# APM32F411 register map
Vendor: Geehy; File version: 2024.11.05
CPU: CM4 r1p0, little endian, 3 interrupt priority bits
Registers are 32-bit, read-write, reset 0x0 unless marked. A register's access mark holds for its fields unless they carry their own. Offsets are from the block's base; [hi:lo] are bit positions.

## I2C1 — Inter-integrated circuit
Base 0x40005400
Same registers: I2C2 0x40005800, I2C3 0x40005C00
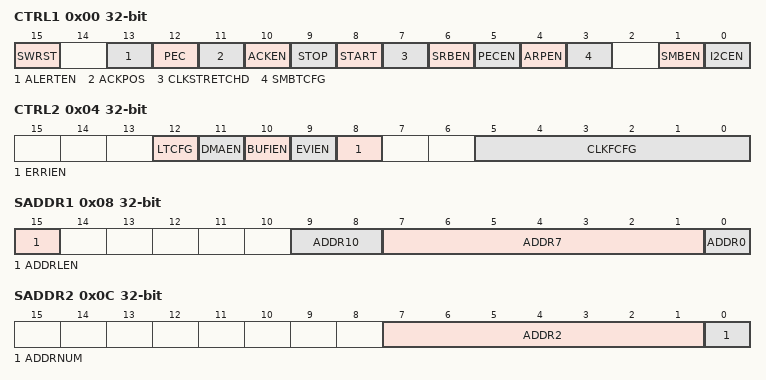
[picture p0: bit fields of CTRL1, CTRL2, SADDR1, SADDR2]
0x00 CTRL1 — Control register 1
  [15] SWRST — Software reset
  [13] ALERTEN — SMBus alert
  [12] PEC — Packet error checking
  [11] ACKPOS — Acknowledge/PEC Position (for data reception)
  [10] ACKEN — Acknowledge enable
  [9] STOP — Stop generation
  [8] START — Start generation
  [7] CLKSTRETCHD — Clock stretching disable (Slave mode)
  [6] SRBEN — General call enable
  [5] PECEN — PEC enable
  [4] ARPEN — ARP enable
  [3] SMBTCFG — SMBus type
  [1] SMBEN — SMBus mode
  [0] I2CEN — I2C enable
0x04 CTRL2 — Control register 2
  [12] LTCFG — DMA last transfer
  [11] DMAEN — DMA requests enable
  [10] BUFIEN — Buffer interrupt enable
  [9] EVIEN — Event interrupt enable
  [8] ERRIEN — Error interrupt enable
  [5:0] CLKFCFG — I2C clock frequency
0x08 SADDR1 — Own address register 1
  [15] ADDRLEN — Addressing mode (slave mode)
  [9:8] ADDR10 — Interface address
  [7:1] ADDR7 — Interface address
  [0] ADDR0 — Interface address
0x0C SADDR2 — Own address register 2
  [7:1] ADDR2 — Interface address
  [0] ADDRNUM — Slave Address Number Configure
0x10 DATA
  [7:0] DATA — 8-bit data register
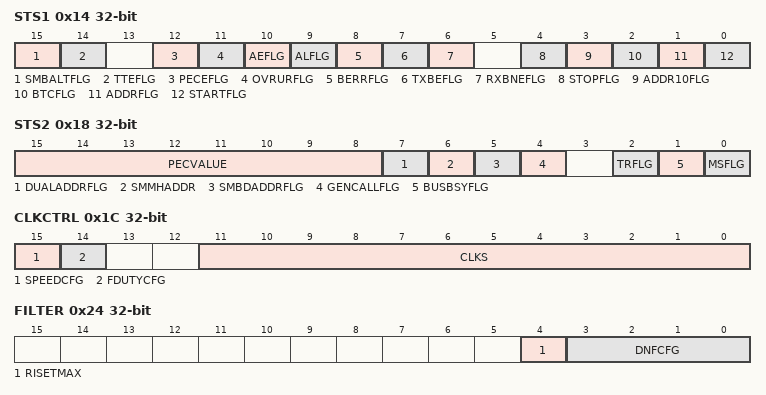
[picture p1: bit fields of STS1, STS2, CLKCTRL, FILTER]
0x14 STS1 access per field — Status register 1
  [15] SMBALTFLG rw — SMBus alert
  [14] TTEFLG rw — Timeout or Tlow error
  [12] PECEFLG rw — PEC Error in reception
  [11] OVRURFLG rw — Overrun/Underrun
  [10] AEFLG rw — Acknowledge failure
  [9] ALFLG rw — Arbitration lost (master mode)
  [8] BERRFLG rw — Bus error
  [7] TXBEFLG ro — Data register empty (transmitters)
  [6] RXBNEFLG ro — Data register not empty (receivers)
  [4] STOPFLG ro — Stop detection (slave mode)
  [3] ADDR10FLG ro — 10-bit header sent (Master mode)
  [2] BTCFLG ro — Byte transfer finished
  [1] ADDRFLG ro — Address sent (master mode)/matched (slavemode)
  [0] STARTFLG ro — Start bit (Master mode)
0x18 STS2 ro — Status register 2
  [15:8] PECVALUE — Save Packet Error Checking Value
  [7] DUALADDRFLG — Dual flag (Slave mode)
  [6] SMMHADDR — SMBus host header (Slave mode)
  [5] SMBDADDRFLG — SMBus device default address (Slave mode)
  [4] GENCALLFLG — General call address (Slave mode)
  [2] TRFLG — Transmitter/receiver
  [1] BUSBSYFLG — Bus busy
  [0] MSFLG — Master Slave Mode Flag
0x1C CLKCTRL — Clock control register
  [15] SPEEDCFG — Master Mode Speed Configure
  [14] FDUTYCFG — Fast mode duty cycle
  [11:0] CLKS — Clock control register in Fast/Standard mode(Master mode)
0x20 RISETMAX reset 0x2 — Maximum Rise Time register
  [5:0] RISETMAX — Maximum rise time in Fast/Standard mode (Master mode)
0x24 FILTER — Filter control register
  [4] RISETMAX — Analog Noise Filter Disable
  [3:0] DNFCFG — Digitial Noise Filter Filtering Capabitity Configure

## I2S2ext — Serial peripheral interface
Base 0x40003400
Same registers: SPI2 0x40003800, SPI3 0x40003C00, I2S3ext 0x40004000, SPI1 0x40013000, SPI4 0x40013400, SPI5 0x40015000
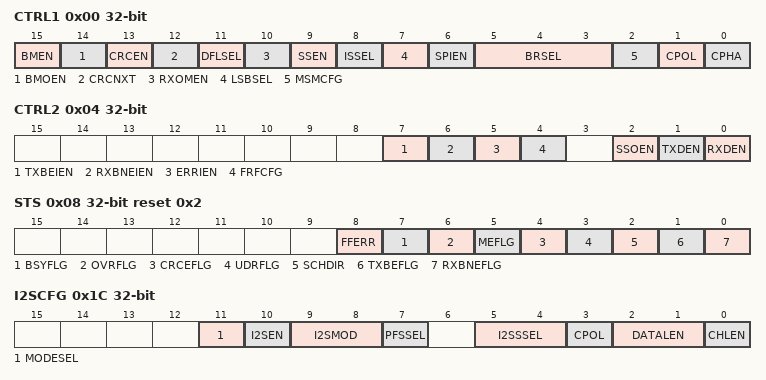
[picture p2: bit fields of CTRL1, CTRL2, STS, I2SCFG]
0x00 CTRL1 — control register 1
  [15] BMEN — Bidirectional data mode enable
  [14] BMOEN — Output enable in bidirectional mode
  [13] CRCEN — Hardware CRC calculation enable
  [12] CRCNXT — CRC transfer next
  [11] DFLSEL — Data frame format
  [10] RXOMEN — Receive only
  [9] SSEN — Software slave management
  [8] ISSEL — Internal slave select
  [7] LSBSEL — Frame format
  [6] SPIEN — SPI enable
  [5:3] BRSEL — Baud rate control
  [2] MSMCFG — Master selection
  [1] CPOL — Clock polarity
  [0] CPHA — Clock phase
0x04 CTRL2 — control register 2
  [7] TXBEIEN — Tx buffer empty interrupt enable
  [6] RXBNEIEN — RX buffer not empty interrupt enable
  [5] ERRIEN — Error interrupt enable
  [4] FRFCFG — Frame Format Configure
  [2] SSOEN — SS output enable
  [1] TXDEN — Tx buffer DMA enable
  [0] RXDEN — Rx buffer DMA enable
0x08 STS access per field reset 0x2 — status register
  [8] FFERR ro — TI frame format error
  [7] BSYFLG ro — Busy flag
  [6] OVRFLG ro — Overrun flag
  [5] MEFLG ro — Mode fault
  [4] CRCEFLG rw — CRC error flag
  [3] UDRFLG ro — Underrun flag
  [2] SCHDIR ro — Channel side
  [1] TXBEFLG ro — Transmit buffer empty
  [0] RXBNEFLG ro — Receive buffer not empty
0x0C DATA
  [15:0] DATA
0x10 CRCPOLY reset 0x7 — CRC polynomial register
  [15:0] CRCPOLY
0x14 RXCRC ro
  [15:0] RXCRC
0x18 TXCRC ro
  [15:0] TXCRC
0x1C I2SCFG — I2S configuration register
  [11] MODESEL — I2S mode selection
  [10] I2SEN — I2S Enable
  [9:8] I2SMOD — I2S configuration mode
  [7] PFSSEL — PCM frame synchronization
  [5:4] I2SSSEL — I2S standard selection
  [3] CPOL — Steady state clock polarity
  [2:1] DATALEN — Data length to be transferred
  [0] CHLEN — Channel length (number of bits per audio channel)
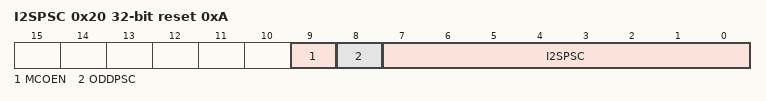
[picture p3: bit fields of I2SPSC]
0x20 I2SPSC reset 0xA — I2S prescaler register
  [9] MCOEN — Master clock output enable
  [8] ODDPSC — Odd factor for the prescaler
  [7:0] I2SPSC — I2S Linear prescaler
